AUTOSAR XML (schema 4-1-3)
standard types defined: boolean, sint8, uint16, uint32, uint8, boolean_CompuMethod, boolean_DataConstr, sint8_DataConstr, uint16_DataConstr, uint32_DataConstr, uint8_DataConstr
package /MICROSAR/Dem_swc/DataTypes
  5 x impl type:
    Dem_DebounceResetStatusType: compu {0=DEM_DEBOUNCE_STATUS_FREEZE, 1=DEM_DEBOUNCE_STATUS_RESET}, range raw 0..255, implementation-data-type=ImplementationDataTypes/uint8
    Dem_DTCFormatType: compu {0=DEM_DTC_FORMAT_OBD, 1=DEM_DTC_FORMAT_UDS, 2=DEM_DTC_FORMAT_J1939}, range raw 0..2, implementation-data-type=ImplementationDataTypes/uint8
    Dem_EventStatusType:
      compu {0=DEM_EVENT_STATUS_PASSED, 1=DEM_EVENT_STATUS_FAILED, 2=DEM_EVENT_STATUS_PREPASSED, 3=DEM_EVENT_STATUS_PREFAILED, 4=DEM_EVENT_STATUS_FDC_THRESHOLD_REACHED, 5=DEM_EVENT_STATUS_PASSED_CONDITIONS_NOT_FULFILLED, 6=DEM_EVENT_STATUS_FAILED_CONDITIONS_NOT_FULFILLED, 7=DEM_EVENT_STATUS_PREPASSED_CONDITIONS_NOT_FULFILLED, 8=DEM_EVENT_STATUS_PREFAILED_CONDITIONS_NOT_FULFILLED}
      range raw 0..255
      implementation-data-type=ImplementationDataTypes/uint8
    Dem_MaxDataValueType: category=ARRAY, sw-calibration-access=READ-ONLY
      element Dem_MaxDataValueTypeElement: array-size=14, array-size-semantics=FIXED-SIZE, implementation-data-type=ImplementationDataTypes/uint8
    Dem_UdsStatusByteType:
      compu {mask 1: 1=DEM_UDS_STATUS_TF (bit 0: TestFailed), mask 2: 2=DEM_UDS_STATUS_TFTOC (bit 1: TestFailedThisOperationCycle), mask 4: 4=DEM_UDS_STATUS_PDTC (bit 2: PendingDTC), mask 8: 8=DEM_UDS_STATUS_CDTC (bit 3: ConfirmedDTC), mask 16: 16=DEM_UDS_STATUS_TNCSLC (bit 4: TestNotCompletedSinceLastClear), mask 32: 32=DEM_UDS_STATUS_TFSLC (bit 5: TestFailedSinceLastClear), mask 64: 64=DEM_UDS_STATUS_TNCTOC (bit 6: TestNotCompletedThisOperationCycle), mask 128: 128=DEM_UDS_STATUS_WIR (bit 7: WarningIndicatorRequested)}
      range raw 0..255
      implementation-data-type=ImplementationDataTypes/uint8
package /MICROSAR/Dem_swc/Interfaces
  client server interface DiagnosticMonitor: is-service=true, service-kind=DIAGNOSTIC-EVENT-MANAGER
    11 x operation:
      GetDTCOfEvent: possible-error=[DEM_E_NO_DTC_AVAILABLE, DiagnosticMonitor/E_NOT_OK]
        arg DTCFormat: type=Dem_DTCFormatType, direction=IN, server-argument-impl-policy=USE-ARGUMENT-TYPE
        arg DTCOfEvent: type=ImplementationDataTypes/uint32, direction=OUT, server-argument-impl-policy=USE-ARGUMENT-TYPE
      GetEventExtendedDataRecordEx: possible-error=[DEM_BUFFER_TOO_SMALL, DEM_NO_SUCH_ELEMENT, DiagnosticMonitor/E_NOT_OK]
        arg RecordNumber: type=ImplementationDataTypes/uint8, direction=IN, server-argument-impl-policy=USE-ARGUMENT-TYPE
        arg DestBuffer: type=Dem_MaxDataValueType, direction=OUT, server-argument-impl-policy=USE-ARGUMENT-TYPE
        arg BufSize: type=ImplementationDataTypes/uint16, direction=INOUT, server-argument-impl-policy=USE-ARGUMENT-TYPE
      GetEventFailed: possible-error=DiagnosticMonitor/E_NOT_OK
        arg EventFailed: type=ImplementationDataTypes/boolean, direction=OUT, server-argument-impl-policy=USE-ARGUMENT-TYPE
      GetEventFreezeFrameDataEx: possible-error=[DEM_BUFFER_TOO_SMALL, DEM_NO_SUCH_ELEMENT, DiagnosticMonitor/E_NOT_OK]
        4 x arg, all with server-argument-impl-policy=USE-ARGUMENT-TYPE:
          RecordNumber: type=ImplementationDataTypes/uint8, direction=IN
          DataId: type=ImplementationDataTypes/uint16, direction=IN
          DestBuffer: type=Dem_MaxDataValueType, direction=OUT
          BufSize: type=ImplementationDataTypes/uint16, direction=INOUT
      GetEventStatus: possible-error=DiagnosticMonitor/E_NOT_OK
        arg UDSStatusByte: type=Dem_UdsStatusByteType, direction=OUT, server-argument-impl-policy=USE-ARGUMENT-TYPE
      GetEventTested: possible-error=DiagnosticMonitor/E_NOT_OK
        arg EventTested: type=ImplementationDataTypes/boolean, direction=OUT, server-argument-impl-policy=USE-ARGUMENT-TYPE
      GetEventUdsStatus: possible-error=DiagnosticMonitor/E_NOT_OK
        arg UDSStatusByte: type=Dem_UdsStatusByteType, direction=OUT, server-argument-impl-policy=USE-ARGUMENT-TYPE
      GetFaultDetectionCounter: possible-error=[DEM_E_NO_FDC_AVAILABLE, DiagnosticMonitor/E_NOT_OK]
        arg FaultDetectionCounter: type=sint8, direction=OUT, server-argument-impl-policy=USE-ARGUMENT-TYPE
      ResetEventDebounceStatus: possible-error=DiagnosticMonitor/E_NOT_OK
        arg DebounceResetStatus: type=Dem_DebounceResetStatusType, direction=IN, server-argument-impl-policy=USE-ARGUMENT-TYPE
      ResetEventStatus: possible-error=DiagnosticMonitor/E_NOT_OK
      SetEventStatus: possible-error=DiagnosticMonitor/E_NOT_OK
        arg EventStatus: type=Dem_EventStatusType, direction=IN, server-argument-impl-policy=USE-ARGUMENT-TYPE
    5 x error:
      DEM_BUFFER_TOO_SMALL: error-code=21
      DEM_E_NO_DTC_AVAILABLE: error-code=10
      DEM_E_NO_FDC_AVAILABLE: error-code=14
      DEM_NO_SUCH_ELEMENT: error-code=48
      E_NOT_OK: error-code=1
package /UAES/ASW/CompuMethods
  compu method CM_boolean: 0=FALSE, 1=TRUE
package /UAES/ASW/DataConstrs
  range DC_boolean: raw 0..1
  range DC_uint16: raw 0..65535
  range DC_uint32: raw 0..4294967295
  range DC_uint8: raw 0..255
package /UAES/ASW/DataTypeMappingSets
  data type mapping set EFuse_Mon
package /UAES/ASW/ImplementationDataTypes
  impl type rt_Array_uint16_25: category=ARRAY, sw-calibration-access=READ-ONLY, type-emitter=RTE
    element rt_Array_uint16_25: array-size=25, array-size-semantics=FIXED-SIZE, implementation-data-type=ImplementationDataTypes/uint16
  impl type rt_Array_uint32_9: category=ARRAY, sw-calibration-access=READ-ONLY, type-emitter=RTE
    element rt_Array_uint32_9: array-size=9, array-size-semantics=FIXED-SIZE, implementation-data-type=ImplementationDataTypes/uint32
  impl type rt_Array_uint8_9: category=ARRAY, sw-calibration-access=READ-ONLY, type-emitter=RTE
    element rt_Array_uint8_9: array-size=9, array-size-semantics=FIXED-SIZE, implementation-data-type=ImplementationDataTypes/uint8
package /UAES/ASW/PortInterfaces
  client server interface EFuse_ActMode_Get
    operation EFuse_SleepState_Get: possible-error=EFuse_ActMode_Get/E_NOT_OK
      arg EFuse_ID: type=ImplementationDataTypes/uint16, direction=IN, server-argument-impl-policy=USE-ARGUMENT-TYPE
      arg SleepState: type=ImplementationDataTypes/uint8, direction=OUT, server-argument-impl-policy=USE-ARGUMENT-TYPE
    error E_NOT_OK: error-code=1
  client server interface EFuse_Current_Get
    operation EFuse_Current_Get: possible-error=EFuse_Current_Get/E_NOT_OK
      arg EFuse_ID: type=ImplementationDataTypes/uint16, direction=IN, server-argument-impl-policy=USE-ARGUMENT-TYPE
      arg CurrRaw: type=ImplementationDataTypes/uint32, direction=OUT, server-argument-impl-policy=USE-ARGUMENT-TYPE
    error E_NOT_OK: error-code=1
  client server interface EFuse_DiagInfo_Get
    operation EFuse_DiagInfo_Get: possible-error=EFuse_DiagInfo_Get/E_NOT_OK
      arg EFuse_ID: type=ImplementationDataTypes/uint16, direction=IN, server-argument-impl-policy=USE-ARGUMENT-TYPE
      arg DiagInfo: type=ImplementationDataTypes/uint32, direction=OUT, server-argument-impl-policy=USE-ARGUMENT-TYPE
    error E_NOT_OK: error-code=1
  7 x sender receiver interface:
    EFuse_au32CurrFild: invalidation-policy{data-element=EFuse_au32CurrFild/Val, handle-invalid=DONT-INVALIDATE}
      data Val: sw-calibration-access=READ-ONLY, type=rt_Array_uint32_9
    EFuse_au32ErrInfo: invalidation-policy{data-element=EFuse_au32ErrInfo/Val, handle-invalid=DONT-INVALIDATE}
      data Val: sw-calibration-access=READ-ONLY, type=rt_Array_uint32_9
    EFuse_au8stFuse: invalidation-policy{data-element=EFuse_au8stFuse/Val, handle-invalid=DONT-INVALIDATE}
      data Val: sw-calibration-access=READ-ONLY, type=rt_Array_uint8_9
    EFuse_au8stSleep: invalidation-policy{data-element=EFuse_au8stSleep/Val, handle-invalid=DONT-INVALIDATE}
      data Val: sw-calibration-access=READ-ONLY, type=rt_Array_uint8_9
    gPRM_au16OvrCurrDebTime: invalidation-policy{data-element=gPRM_au16OvrCurrDebTime/Val, handle-invalid=DONT-INVALIDATE}
      data Val: sw-calibration-access=READ-ONLY, type=rt_Array_uint16_25
    gPRM_au16OvrCurrThres: invalidation-policy{data-element=gPRM_au16OvrCurrThres/Val, handle-invalid=DONT-INVALIDATE}
      data Val: sw-calibration-access=READ-ONLY, type=rt_Array_uint16_25
    gVRM_u16BatteryVolt_mv: invalidation-policy{data-element=gVRM_u16BatteryVolt_mv/Val, handle-invalid=DONT-INVALIDATE}
      data Val: sw-calibration-access=READ-ONLY, type=ImplementationDataTypes/uint16
package /UAES/ASW/SwAddrMethods
  sw addr method CALDATA
package /UAES/ASW/SwComponentTypes
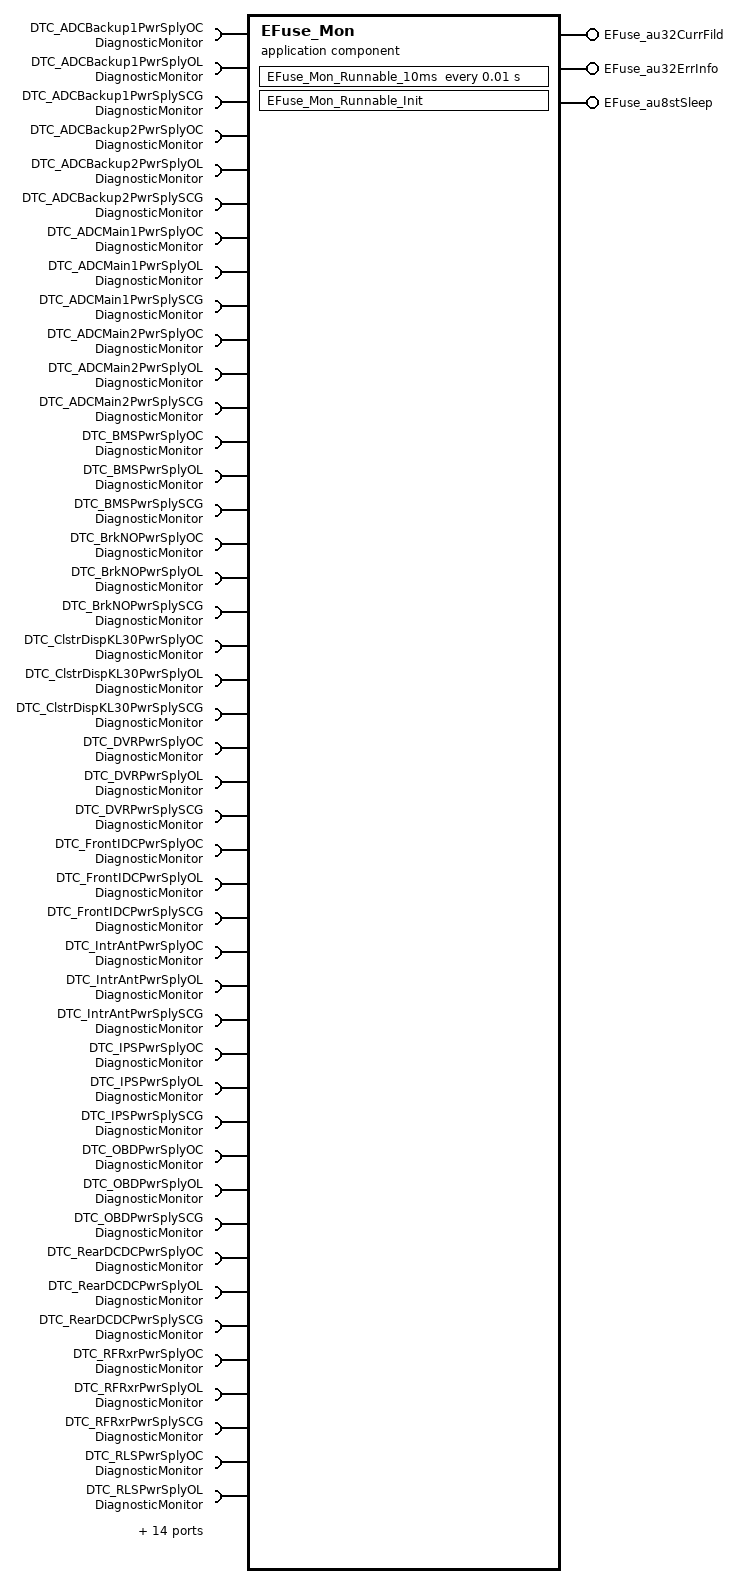
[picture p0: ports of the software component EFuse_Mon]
  application sw component type EFuse_Mon
    provide port EFuse_au32CurrFild: nonqueued-sender-com-spec{data-element=EFuse_au32CurrFild/Val, init-value=9 x 0}, provided-interface=EFuse_au32CurrFild
    provide port EFuse_au32ErrInfo: nonqueued-sender-com-spec{data-element=EFuse_au32ErrInfo/Val, init-value=9 x 0}, provided-interface=EFuse_au32ErrInfo
    provide port EFuse_au8stSleep: nonqueued-sender-com-spec{data-element=EFuse_au8stSleep/Val, init-value=9 x 0}, provided-interface=EFuse_au8stSleep
    58 x require port:
      DTC_ADCBackup1PwrSplyOC: required-interface=DiagnosticMonitor
        required-com-specs:
          GetDTCOfEvent
          GetEventExtendedDataRecordEx
          GetEventFailed
          GetEventFreezeFrameDataEx
          GetEventStatus
          GetEventTested
          GetEventUdsStatus
          GetFaultDetectionCounter
          ResetEventDebounceStatus
          ResetEventStatus
          SetEventStatus
      DTC_ADCBackup1PwrSplyOL: required-interface=DiagnosticMonitor
        required-com-specs:
          GetDTCOfEvent
          GetEventExtendedDataRecordEx
          GetEventFailed
          GetEventFreezeFrameDataEx
          GetEventStatus
          GetEventTested
          GetEventUdsStatus
          GetFaultDetectionCounter
          ResetEventDebounceStatus
          ResetEventStatus
          SetEventStatus
      DTC_ADCBackup1PwrSplySCG: required-interface=DiagnosticMonitor
        required-com-specs:
          GetDTCOfEvent
          GetEventExtendedDataRecordEx
          GetEventFailed
          GetEventFreezeFrameDataEx
          GetEventStatus
          GetEventTested
          GetEventUdsStatus
          GetFaultDetectionCounter
          ResetEventDebounceStatus
          ResetEventStatus
          SetEventStatus
      DTC_ADCBackup2PwrSplyOC: required-interface=DiagnosticMonitor
        required-com-specs:
          GetDTCOfEvent
          GetEventExtendedDataRecordEx
          GetEventFailed
          GetEventFreezeFrameDataEx
          GetEventStatus
          GetEventTested
          GetEventUdsStatus
          GetFaultDetectionCounter
          ResetEventDebounceStatus
          ResetEventStatus
          SetEventStatus
      DTC_ADCBackup2PwrSplyOL: required-interface=DiagnosticMonitor
        required-com-specs:
          GetDTCOfEvent
          GetEventExtendedDataRecordEx
          GetEventFailed
          GetEventFreezeFrameDataEx
          GetEventStatus
          GetEventTested
          GetEventUdsStatus
          GetFaultDetectionCounter
          ResetEventDebounceStatus
          ResetEventStatus
          SetEventStatus
      DTC_ADCBackup2PwrSplySCG: required-interface=DiagnosticMonitor
        required-com-specs:
          GetDTCOfEvent
          GetEventExtendedDataRecordEx
          GetEventFailed
          GetEventFreezeFrameDataEx
          GetEventStatus
          GetEventTested
          GetEventUdsStatus
          GetFaultDetectionCounter
          ResetEventDebounceStatus
          ResetEventStatus
          SetEventStatus
      DTC_ADCMain1PwrSplyOC: required-interface=DiagnosticMonitor
        required-com-specs:
          GetDTCOfEvent
          GetEventExtendedDataRecordEx
          GetEventFailed
          GetEventFreezeFrameDataEx
          GetEventStatus
          GetEventTested
          GetEventUdsStatus
          GetFaultDetectionCounter
          ResetEventDebounceStatus
          ResetEventStatus
          SetEventStatus
      DTC_ADCMain1PwrSplyOL: required-interface=DiagnosticMonitor
        required-com-specs:
          GetDTCOfEvent
          GetEventExtendedDataRecordEx
          GetEventFailed
          GetEventFreezeFrameDataEx
          GetEventStatus
          GetEventTested
          GetEventUdsStatus
          GetFaultDetectionCounter
          ResetEventDebounceStatus
          ResetEventStatus
          SetEventStatus
      DTC_ADCMain1PwrSplySCG: required-interface=DiagnosticMonitor
        required-com-specs:
          GetDTCOfEvent
          GetEventExtendedDataRecordEx
          GetEventFailed
          GetEventFreezeFrameDataEx
          GetEventStatus
          GetEventTested
          GetEventUdsStatus
          GetFaultDetectionCounter
          ResetEventDebounceStatus
          ResetEventStatus
          SetEventStatus
      DTC_ADCMain2PwrSplyOC: required-interface=DiagnosticMonitor
        required-com-specs:
          GetDTCOfEvent
          GetEventExtendedDataRecordEx
          GetEventFailed
          GetEventFreezeFrameDataEx
          GetEventStatus
          GetEventTested
          GetEventUdsStatus
          GetFaultDetectionCounter
          ResetEventDebounceStatus
          ResetEventStatus
          SetEventStatus
      DTC_ADCMain2PwrSplyOL: required-interface=DiagnosticMonitor
        required-com-specs:
          GetDTCOfEvent
          GetEventExtendedDataRecordEx
          GetEventFailed
          GetEventFreezeFrameDataEx
          GetEventStatus
          GetEventTested
          GetEventUdsStatus
          GetFaultDetectionCounter
          ResetEventDebounceStatus
          ResetEventStatus
          SetEventStatus
      DTC_ADCMain2PwrSplySCG: required-interface=DiagnosticMonitor
        required-com-specs:
          GetDTCOfEvent
          GetEventExtendedDataRecordEx
          GetEventFailed
          GetEventFreezeFrameDataEx
          GetEventStatus
          GetEventTested
          GetEventUdsStatus
          GetFaultDetectionCounter
          ResetEventDebounceStatus
          ResetEventStatus
          SetEventStatus
      DTC_BMSPwrSplyOC: required-interface=DiagnosticMonitor
        required-com-specs:
          GetDTCOfEvent
          GetEventExtendedDataRecordEx
          GetEventFailed
          GetEventFreezeFrameDataEx
          GetEventStatus
          GetEventTested
          GetEventUdsStatus
          GetFaultDetectionCounter
          ResetEventDebounceStatus
          ResetEventStatus
          SetEventStatus
      DTC_BMSPwrSplyOL: required-interface=DiagnosticMonitor
        required-com-specs:
          GetDTCOfEvent
          GetEventExtendedDataRecordEx
          GetEventFailed
          GetEventFreezeFrameDataEx
          GetEventStatus
          GetEventTested
          GetEventUdsStatus
          GetFaultDetectionCounter
          ResetEventDebounceStatus
          ResetEventStatus
          SetEventStatus
      DTC_BMSPwrSplySCG: required-interface=DiagnosticMonitor
        required-com-specs:
          GetDTCOfEvent
          GetEventExtendedDataRecordEx
          GetEventFailed
          GetEventFreezeFrameDataEx
          GetEventStatus
          GetEventTested
          GetEventUdsStatus
          GetFaultDetectionCounter
          ResetEventDebounceStatus
          ResetEventStatus
          SetEventStatus
      DTC_BrkNOPwrSplyOC: required-interface=DiagnosticMonitor
        required-com-specs:
          GetDTCOfEvent
          GetEventExtendedDataRecordEx
          GetEventFailed
          GetEventFreezeFrameDataEx
          GetEventStatus
          GetEventTested
          GetEventUdsStatus
          GetFaultDetectionCounter
          ResetEventDebounceStatus
          ResetEventStatus
          SetEventStatus
      DTC_BrkNOPwrSplyOL: required-interface=DiagnosticMonitor
        required-com-specs:
          GetDTCOfEvent
          GetEventExtendedDataRecordEx
          GetEventFailed
          GetEventFreezeFrameDataEx
          GetEventStatus
          GetEventTested
          GetEventUdsStatus
          GetFaultDetectionCounter
          ResetEventDebounceStatus
          ResetEventStatus
          SetEventStatus
      DTC_BrkNOPwrSplySCG: required-interface=DiagnosticMonitor
        required-com-specs:
          GetDTCOfEvent
          GetEventExtendedDataRecordEx
          GetEventFailed
          GetEventFreezeFrameDataEx
          GetEventStatus
          GetEventTested
          GetEventUdsStatus
          GetFaultDetectionCounter
          ResetEventDebounceStatus
          ResetEventStatus
          SetEventStatus
      DTC_ClstrDispKL30PwrSplyOC: required-interface=DiagnosticMonitor
        required-com-specs:
          GetDTCOfEvent
          GetEventExtendedDataRecordEx
          GetEventFailed
          GetEventFreezeFrameDataEx
          GetEventStatus
          GetEventTested
          GetEventUdsStatus
          GetFaultDetectionCounter
          ResetEventDebounceStatus
          ResetEventStatus
          SetEventStatus
      DTC_ClstrDispKL30PwrSplyOL: required-interface=DiagnosticMonitor
        required-com-specs:
          GetDTCOfEvent
          GetEventExtendedDataRecordEx
          GetEventFailed
          GetEventFreezeFrameDataEx
          GetEventStatus
          GetEventTested
          GetEventUdsStatus
          GetFaultDetectionCounter
          ResetEventDebounceStatus
          ResetEventStatus
          SetEventStatus
      DTC_ClstrDispKL30PwrSplySCG: required-interface=DiagnosticMonitor
        required-com-specs:
          GetDTCOfEvent
          GetEventExtendedDataRecordEx
          GetEventFailed
          GetEventFreezeFrameDataEx
          GetEventStatus
          GetEventTested
          GetEventUdsStatus
          GetFaultDetectionCounter
          ResetEventDebounceStatus
          ResetEventStatus
          SetEventStatus
      DTC_DVRPwrSplyOC: required-interface=DiagnosticMonitor
        required-com-specs:
          GetDTCOfEvent
          GetEventExtendedDataRecordEx
          GetEventFailed
          GetEventFreezeFrameDataEx
          GetEventStatus
          GetEventTested
          GetEventUdsStatus
          GetFaultDetectionCounter
          ResetEventDebounceStatus
          ResetEventStatus
          SetEventStatus
      DTC_DVRPwrSplyOL: required-interface=DiagnosticMonitor
        required-com-specs:
          GetDTCOfEvent
          GetEventExtendedDataRecordEx
          GetEventFailed
          GetEventFreezeFrameDataEx
          GetEventStatus
          GetEventTested
          GetEventUdsStatus
          GetFaultDetectionCounter
          ResetEventDebounceStatus
          ResetEventStatus
          SetEventStatus
      DTC_DVRPwrSplySCG: required-interface=DiagnosticMonitor
        required-com-specs:
          GetDTCOfEvent
          GetEventExtendedDataRecordEx
          GetEventFailed
          GetEventFreezeFrameDataEx
          GetEventStatus
          GetEventTested
          GetEventUdsStatus
          GetFaultDetectionCounter
          ResetEventDebounceStatus
          ResetEventStatus
          SetEventStatus
      DTC_FrontIDCPwrSplyOC: required-interface=DiagnosticMonitor
        required-com-specs:
          GetDTCOfEvent
          GetEventExtendedDataRecordEx
          GetEventFailed
          GetEventFreezeFrameDataEx
          GetEventStatus
          GetEventTested
          GetEventUdsStatus
          GetFaultDetectionCounter
          ResetEventDebounceStatus
          ResetEventStatus
          SetEventStatus
      DTC_FrontIDCPwrSplyOL: required-interface=DiagnosticMonitor
        required-com-specs:
          GetDTCOfEvent
          GetEventExtendedDataRecordEx
          GetEventFailed
          GetEventFreezeFrameDataEx
          GetEventStatus
          GetEventTested
          GetEventUdsStatus
          GetFaultDetectionCounter
          ResetEventDebounceStatus
          ResetEventStatus
          SetEventStatus
      DTC_FrontIDCPwrSplySCG: required-interface=DiagnosticMonitor
        required-com-specs:
          GetDTCOfEvent
          GetEventExtendedDataRecordEx
          GetEventFailed
          GetEventFreezeFrameDataEx
          GetEventStatus
          GetEventTested
          GetEventUdsStatus
          GetFaultDetectionCounter
          ResetEventDebounceStatus
          ResetEventStatus
          SetEventStatus
      DTC_IntrAntPwrSplyOC: required-interface=DiagnosticMonitor
        required-com-specs:
          GetDTCOfEvent
          GetEventExtendedDataRecordEx
          GetEventFailed
          GetEventFreezeFrameDataEx
          GetEventStatus
          GetEventTested
          GetEventUdsStatus
          GetFaultDetectionCounter
          ResetEventDebounceStatus
          ResetEventStatus
          SetEventStatus
      DTC_IntrAntPwrSplyOL: required-interface=DiagnosticMonitor
        required-com-specs:
          GetDTCOfEvent
          GetEventExtendedDataRecordEx
          GetEventFailed
          GetEventFreezeFrameDataEx
          GetEventStatus
          GetEventTested
          GetEventUdsStatus
          GetFaultDetectionCounter
          ResetEventDebounceStatus
          ResetEventStatus
          SetEventStatus
      DTC_IntrAntPwrSplySCG: required-interface=DiagnosticMonitor
        required-com-specs:
          GetDTCOfEvent
          GetEventExtendedDataRecordEx
          GetEventFailed
          GetEventFreezeFrameDataEx
          GetEventStatus
          GetEventTested
          GetEventUdsStatus
          GetFaultDetectionCounter
          ResetEventDebounceStatus
          ResetEventStatus
          SetEventStatus
      DTC_IPSPwrSplyOC: required-interface=DiagnosticMonitor
        required-com-specs:
          GetDTCOfEvent
          GetEventExtendedDataRecordEx
          GetEventFailed
          GetEventFreezeFrameDataEx
          GetEventStatus
          GetEventTested
          GetEventUdsStatus
          GetFaultDetectionCounter
          ResetEventDebounceStatus
          ResetEventStatus
          SetEventStatus
      DTC_IPSPwrSplyOL: required-interface=DiagnosticMonitor
        required-com-specs:
          GetDTCOfEvent
          GetEventExtendedDataRecordEx
          GetEventFailed
          GetEventFreezeFrameDataEx
          GetEventStatus
          GetEventTested
          GetEventUdsStatus
          GetFaultDetectionCounter
          ResetEventDebounceStatus
          ResetEventStatus
          SetEventStatus
      DTC_IPSPwrSplySCG: required-interface=DiagnosticMonitor
        required-com-specs:
          GetDTCOfEvent
          GetEventExtendedDataRecordEx
          GetEventFailed
          GetEventFreezeFrameDataEx
          GetEventStatus
          GetEventTested
          GetEventUdsStatus
          GetFaultDetectionCounter
          ResetEventDebounceStatus
          ResetEventStatus
          SetEventStatus
      DTC_OBDPwrSplyOC: required-interface=DiagnosticMonitor
        required-com-specs:
          GetDTCOfEvent
          GetEventExtendedDataRecordEx
          GetEventFailed
          GetEventFreezeFrameDataEx
          GetEventStatus
          GetEventTested
          GetEventUdsStatus
          GetFaultDetectionCounter
          ResetEventDebounceStatus
          ResetEventStatus
          SetEventStatus
      DTC_OBDPwrSplyOL: required-interface=DiagnosticMonitor
        required-com-specs:
          GetDTCOfEvent
          GetEventExtendedDataRecordEx
          GetEventFailed
          GetEventFreezeFrameDataEx
          GetEventStatus
          GetEventTested
          GetEventUdsStatus
          GetFaultDetectionCounter
          ResetEventDebounceStatus
          ResetEventStatus
          SetEventStatus
      DTC_OBDPwrSplySCG: required-interface=DiagnosticMonitor
        required-com-specs:
          GetDTCOfEvent
          GetEventExtendedDataRecordEx
          GetEventFailed
          GetEventFreezeFrameDataEx
          GetEventStatus
          GetEventTested
          GetEventUdsStatus
          GetFaultDetectionCounter
          ResetEventDebounceStatus
          ResetEventStatus
          SetEventStatus
      DTC_RearDCDCPwrSplyOC: required-interface=DiagnosticMonitor
        required-com-specs:
          GetDTCOfEvent
          GetEventExtendedDataRecordEx
          GetEventFailed
          GetEventFreezeFrameDataEx
          GetEventStatus
          GetEventTested
          GetEventUdsStatus
          GetFaultDetectionCounter
          ResetEventDebounceStatus
          ResetEventStatus
          SetEventStatus
      DTC_RearDCDCPwrSplyOL: required-interface=DiagnosticMonitor
        required-com-specs:
          GetDTCOfEvent
          GetEventExtendedDataRecordEx
          GetEventFailed
          GetEventFreezeFrameDataEx
          GetEventStatus
          GetEventTested
          GetEventUdsStatus
          GetFaultDetectionCounter
          ResetEventDebounceStatus
          ResetEventStatus
          SetEventStatus
      DTC_RearDCDCPwrSplySCG: required-interface=DiagnosticMonitor
        required-com-specs:
          GetDTCOfEvent
          GetEventExtendedDataRecordEx
          GetEventFailed
          GetEventFreezeFrameDataEx
          GetEventStatus
          GetEventTested
          GetEventUdsStatus
          GetFaultDetectionCounter
          ResetEventDebounceStatus
          ResetEventStatus
          SetEventStatus
      DTC_RFRxrPwrSplyOC: required-interface=DiagnosticMonitor
        required-com-specs:
          GetDTCOfEvent
          GetEventExtendedDataRecordEx
          GetEventFailed
          GetEventFreezeFrameDataEx
          GetEventStatus
          GetEventTested
          GetEventUdsStatus
          GetFaultDetectionCounter
          ResetEventDebounceStatus
          ResetEventStatus
          SetEventStatus
      DTC_RFRxrPwrSplyOL: required-interface=DiagnosticMonitor
        required-com-specs:
          GetDTCOfEvent
          GetEventExtendedDataRecordEx
          GetEventFailed
          GetEventFreezeFrameDataEx
          GetEventStatus
          GetEventTested
          GetEventUdsStatus
          GetFaultDetectionCounter
          ResetEventDebounceStatus
          ResetEventStatus
          SetEventStatus
      DTC_RFRxrPwrSplySCG: required-interface=DiagnosticMonitor
        required-com-specs:
          GetDTCOfEvent
          GetEventExtendedDataRecordEx
          GetEventFailed
          GetEventFreezeFrameDataEx
          GetEventStatus
          GetEventTested
          GetEventUdsStatus
          GetFaultDetectionCounter
          ResetEventDebounceStatus
          ResetEventStatus
          SetEventStatus
      DTC_RLSPwrSplyOC: required-interface=DiagnosticMonitor
        required-com-specs:
          GetDTCOfEvent
          GetEventExtendedDataRecordEx
          GetEventFailed
          GetEventFreezeFrameDataEx
          GetEventStatus
          GetEventTested
          GetEventUdsStatus
          GetFaultDetectionCounter
          ResetEventDebounceStatus
          ResetEventStatus
          SetEventStatus
      DTC_RLSPwrSplyOL: required-interface=DiagnosticMonitor
        required-com-specs:
          GetDTCOfEvent
          GetEventExtendedDataRecordEx
          GetEventFailed
          GetEventFreezeFrameDataEx
          GetEventStatus
          GetEventTested
          GetEventUdsStatus
          GetFaultDetectionCounter
          ResetEventDebounceStatus
          ResetEventStatus
          SetEventStatus
      DTC_RLSPwrSplySCG: required-interface=DiagnosticMonitor
        required-com-specs:
          GetDTCOfEvent
          GetEventExtendedDataRecordEx
          GetEventFailed
          GetEventFreezeFrameDataEx
          GetEventStatus
          GetEventTested
          GetEventUdsStatus
          GetFaultDetectionCounter
          ResetEventDebounceStatus
          ResetEventStatus
          SetEventStatus
      DTC_SAMPwrSplyOC: required-interface=DiagnosticMonitor
        required-com-specs:
          GetDTCOfEvent
          GetEventExtendedDataRecordEx
          GetEventFailed
          GetEventFreezeFrameDataEx
          GetEventStatus
          GetEventTested
          GetEventUdsStatus
          GetFaultDetectionCounter
          ResetEventDebounceStatus
          ResetEventStatus
          SetEventStatus
      DTC_SAMPwrSplyOL: required-interface=DiagnosticMonitor
        required-com-specs:
          GetDTCOfEvent
          GetEventExtendedDataRecordEx
          GetEventFailed
          GetEventFreezeFrameDataEx
          GetEventStatus
          GetEventTested
          GetEventUdsStatus
          GetFaultDetectionCounter
          ResetEventDebounceStatus
          ResetEventStatus
          SetEventStatus
      DTC_SAMPwrSplySCG: required-interface=DiagnosticMonitor
        required-com-specs:
          GetDTCOfEvent
          GetEventExtendedDataRecordEx
          GetEventFailed
          GetEventFreezeFrameDataEx
          GetEventStatus
          GetEventTested
          GetEventUdsStatus
          GetFaultDetectionCounter
          ResetEventDebounceStatus
          ResetEventStatus
          SetEventStatus
      DTC_TBoxPwrSplyOC: required-interface=DiagnosticMonitor
        required-com-specs:
          GetDTCOfEvent
          GetEventExtendedDataRecordEx
          GetEventFailed
          GetEventFreezeFrameDataEx
          GetEventStatus
          GetEventTested
          GetEventUdsStatus
          GetFaultDetectionCounter
          ResetEventDebounceStatus
          ResetEventStatus
          SetEventStatus
      DTC_TBoxPwrSplyOL: required-interface=DiagnosticMonitor
        required-com-specs:
          GetDTCOfEvent
          GetEventExtendedDataRecordEx
          GetEventFailed
          GetEventFreezeFrameDataEx
          GetEventStatus
          GetEventTested
          GetEventUdsStatus
          GetFaultDetectionCounter
          ResetEventDebounceStatus
          ResetEventStatus
          SetEventStatus
      DTC_TBoxPwrSplySCG: required-interface=DiagnosticMonitor
        required-com-specs:
          GetDTCOfEvent
          GetEventExtendedDataRecordEx
          GetEventFailed
          GetEventFreezeFrameDataEx
          GetEventStatus
          GetEventTested
          GetEventUdsStatus
          GetFaultDetectionCounter
          ResetEventDebounceStatus
          ResetEventStatus
          SetEventStatus
      EFuse_ActMode_Get: client-com-spec=EFuse_SleepState_Get, required-interface=EFuse_ActMode_Get
      EFuse_au8stFuse: nonqueued-receiver-com-spec{data-element=EFuse_au8stFuse/Val, filter=data-filter-type=ALWAYS, init-value=9 x 0}, required-interface=EFuse_au8stFuse
      EFuse_Current_Get: client-com-spec=EFuse_Current_Get, required-interface=EFuse_Current_Get
      EFuse_DiagInfo_Get: client-com-spec=EFuse_DiagInfo_Get, required-interface=EFuse_DiagInfo_Get
      gPRM_au16OvrCurrDebTime: nonqueued-receiver-com-spec{data-element=gPRM_au16OvrCurrDebTime/Val, filter=data-filter-type=ALWAYS, init-value=25 x 500}, required-interface=gPRM_au16OvrCurrDebTime
      gPRM_au16OvrCurrThres: nonqueued-receiver-com-spec{data-element=gPRM_au16OvrCurrThres/Val, filter=data-filter-type=ALWAYS, init-value=[65535, 65535, 65535, 22000, 25700, 65535, 65535, 65535, 65535, 65535, 65535, 65535, 33000, 28000, 28000, 9500, 1700, 1700, 65535, 65535, 65535, 65535, 65535, 65535, 65535]}, required-interface=gPRM_au16OvrCurrThres
      gVRM_u16BatteryVolt_mv: nonqueued-receiver-com-spec{data-element=gVRM_u16BatteryVolt_mv/Val, filter=data-filter-type=ALWAYS, init-value=0}, required-interface=gVRM_u16BatteryVolt_mv
    behavior EFuse_Mon_InternalBehavior: data-type-mapping=EFuse_Mon
      timing event TMT_EFuse_Mon_Runnable_10ms: start-on-event=EFuse_Mon_Runnable_10ms, period=0.01
      init event EFuse_Mon_Runnable_InitEvent: start-on-event=EFuse_Mon_Runnable_Init
      runnable EFuse_Mon_Runnable_10ms
        data-read-access:
          4 x access:
            READ_EFuse_au8stFuse_Val: accessed-variable=EFuse_au8stFuse.Val
            READ_gPRM_au16OvrCurrDebTime_Val: accessed-variable=gPRM_au16OvrCurrDebTime.Val
            READ_gPRM_au16OvrCurrThres_Val: accessed-variable=gPRM_au16OvrCurrThres.Val
            READ_gVRM_u16BatteryVolt_mv_Val: accessed-variable=gVRM_u16BatteryVolt_mv.Val
        data-write-access:
          access WRITE_EFuse_au32CurrRaw_Val: accessed-variable=EFuse_au32CurrFild.Val
          access WRITE_EFuse_au32ErrInfo_Val: accessed-variable=EFuse_au32ErrInfo.Val
          access WRITE_EFuse_au8stSleep_Val: accessed-variable=EFuse_au8stSleep.Val
        37 x parameter access:
          PA_EFuse_EnFuse{01..09}TestMod_C: accessed-parameter=EFuse_EnFuse{01..09}TestMod_C
          PA_EFuse_EnProtThdCal_C: accessed-parameter=EFuse_EnProtThdCal_C
          PA_EFuse_iFuse01ProtThd_C: accessed-parameter=EFuse_iFuse01ProtThd_C
          PA_EFuse_iFuse01TestMod_C: accessed-parameter=EFuse_iFuse01TestMod_C
          PA_EFuse_iFuse02ProtThd_C: accessed-parameter=EFuse_iFuse02ProtThd_C
          PA_EFuse_iFuse02TestMod_C: accessed-parameter=EFuse_iFuse02TestMod_C
          PA_EFuse_iFuse03ProtThd_C: accessed-parameter=EFuse_iFuse03ProtThd_C
          PA_EFuse_iFuse03TestMod_C: accessed-parameter=EFuse_iFuse03TestMod_C
          PA_EFuse_iFuse04ProtThd_C: accessed-parameter=EFuse_iFuse04ProtThd_C
          PA_EFuse_iFuse04TestMod_C: accessed-parameter=EFuse_iFuse04TestMod_C
          PA_EFuse_iFuse05ProtThd_C: accessed-parameter=EFuse_iFuse05ProtThd_C
          PA_EFuse_iFuse05TestMod_C: accessed-parameter=EFuse_iFuse05TestMod_C
          PA_EFuse_iFuse06ProtThd_C: accessed-parameter=EFuse_iFuse06ProtThd_C
          PA_EFuse_iFuse06TestMod_C: accessed-parameter=EFuse_iFuse06TestMod_C
          PA_EFuse_iFuse07ProtThd_C: accessed-parameter=EFuse_iFuse07ProtThd_C
          PA_EFuse_iFuse07TestMod_C: accessed-parameter=EFuse_iFuse07TestMod_C
          PA_EFuse_iFuse08ProtThd_C: accessed-parameter=EFuse_iFuse08ProtThd_C
          PA_EFuse_iFuse08TestMod_C: accessed-parameter=EFuse_iFuse08TestMod_C
          PA_EFuse_iFuse09ProtThd_C: accessed-parameter=EFuse_iFuse09ProtThd_C
          PA_EFuse_iFuse09TestMod_C: accessed-parameter=EFuse_iFuse09TestMod_C
          PA_EFuse_tiFuse{01..09}ProtEquivThd_C: accessed-parameter=EFuse_tiFuse{01..09}ProtEquivThd_C
        39 x sync call:
          SC_DTC_ADCBackup1PwrSplyOC_GetEventFailed: operation=DTC_ADCBackup1PwrSplyOC.GetEventFailed, timeout=1E-06
          SC_DTC_ADCBackup1PwrSplyOC_GetEventTested: operation=DTC_ADCBackup1PwrSplyOC.GetEventTested, timeout=1E-06
          SC_DTC_ADCBackup1PwrSplyOC_ResetEventDebounceStatus: operation=DTC_ADCBackup1PwrSplyOC.ResetEventDebounceStatus, timeout=1E-06
          SC_DTC_ADCBackup1PwrSplyOC_SetEventStatus: operation=DTC_ADCBackup1PwrSplyOC.SetEventStatus, timeout=1E-06
          SC_DTC_ADCBackup1PwrSplyOL_GetEventFailed: operation=DTC_ADCBackup1PwrSplyOL.GetEventFailed, timeout=1E-06
          SC_DTC_ADCBackup1PwrSplyOL_GetEventTested: operation=DTC_ADCBackup1PwrSplyOL.GetEventTested, timeout=1E-06
          SC_DTC_ADCBackup1PwrSplyOL_ResetEventDebounceStatus: operation=DTC_ADCBackup1PwrSplyOL.ResetEventDebounceStatus, timeout=1E-06
          SC_DTC_ADCBackup1PwrSplyOL_SetEventStatus: operation=DTC_ADCBackup1PwrSplyOL.SetEventStatus, timeout=1E-06
          SC_DTC_ADCBackup1PwrSplySCG_GetEventFailed: operation=DTC_ADCBackup1PwrSplySCG.GetEventFailed, timeout=1E-06
          SC_DTC_ADCBackup1PwrSplySCG_GetEventTested: operation=DTC_ADCBackup1PwrSplySCG.GetEventTested, timeout=1E-06
          SC_DTC_ADCBackup1PwrSplySCG_ResetEventDebounceStatus: operation=DTC_ADCBackup1PwrSplySCG.ResetEventDebounceStatus, timeout=1E-06
          SC_DTC_ADCBackup1PwrSplySCG_SetEventStatus: operation=DTC_ADCBackup1PwrSplySCG.SetEventStatus, timeout=1E-06
          SC_DTC_ADCBackup2PwrSplyOC_GetEventFailed: operation=DTC_ADCBackup2PwrSplyOC.GetEventFailed, timeout=1E-06
          SC_DTC_ADCBackup2PwrSplyOC_GetEventTested: operation=DTC_ADCBackup2PwrSplyOC.GetEventTested, timeout=1E-06
          SC_DTC_ADCBackup2PwrSplyOC_ResetEventDebounceStatus: operation=DTC_ADCBackup2PwrSplyOC.ResetEventDebounceStatus, timeout=1E-06
          SC_DTC_ADCBackup2PwrSplyOC_SetEventStatus: operation=DTC_ADCBackup2PwrSplyOC.SetEventStatus, timeout=1E-06
          SC_DTC_ADCBackup2PwrSplyOL_GetEventFailed: operation=DTC_ADCBackup2PwrSplyOL.GetEventFailed, timeout=1E-06
          SC_DTC_ADCBackup2PwrSplyOL_GetEventTested: operation=DTC_ADCBackup2PwrSplyOL.GetEventTested, timeout=1E-06
          SC_DTC_ADCBackup2PwrSplyOL_ResetEventDebounceStatus: operation=DTC_ADCBackup2PwrSplyOL.ResetEventDebounceStatus, timeout=1E-06
          SC_DTC_ADCBackup2PwrSplyOL_SetEventStatus: operation=DTC_ADCBackup2PwrSplyOL.SetEventStatus, timeout=1E-06
          SC_DTC_ADCBackup2PwrSplySCG_GetEventFailed: operation=DTC_ADCBackup2PwrSplySCG.GetEventFailed, timeout=1E-06
          SC_DTC_ADCBackup2PwrSplySCG_GetEventTested: operation=DTC_ADCBackup2PwrSplySCG.GetEventTested, timeout=1E-06
          SC_DTC_ADCBackup2PwrSplySCG_ResetEventDebounceStatus: operation=DTC_ADCBackup2PwrSplySCG.ResetEventDebounceStatus, timeout=1E-06
          SC_DTC_ADCBackup2PwrSplySCG_SetEventStatus: operation=DTC_ADCBackup2PwrSplySCG.SetEventStatus, timeout=1E-06
          SC_DTC_RearDCDCPwrSplyOC_GetEventFailed: operation=DTC_RearDCDCPwrSplyOC.GetEventFailed, timeout=1E-06
          SC_DTC_RearDCDCPwrSplyOC_GetEventTested: operation=DTC_RearDCDCPwrSplyOC.GetEventTested, timeout=1E-06
          SC_DTC_RearDCDCPwrSplyOC_ResetEventDebounceStatus: operation=DTC_RearDCDCPwrSplyOC.ResetEventDebounceStatus, timeout=1E-06
          SC_DTC_RearDCDCPwrSplyOC_SetEventStatus: operation=DTC_RearDCDCPwrSplyOC.SetEventStatus, timeout=1E-06
          SC_DTC_RearDCDCPwrSplyOL_GetEventFailed: operation=DTC_RearDCDCPwrSplyOL.GetEventFailed, timeout=1E-06
          SC_DTC_RearDCDCPwrSplyOL_GetEventTested: operation=DTC_RearDCDCPwrSplyOL.GetEventTested, timeout=1E-06
          SC_DTC_RearDCDCPwrSplyOL_ResetEventDebounceStatus: operation=DTC_RearDCDCPwrSplyOL.ResetEventDebounceStatus, timeout=1E-06
          SC_DTC_RearDCDCPwrSplyOL_SetEventStatus: operation=DTC_RearDCDCPwrSplyOL.SetEventStatus, timeout=1E-06
          SC_DTC_RearDCDCPwrSplySCG_GetEventFailed: operation=DTC_RearDCDCPwrSplySCG.GetEventFailed, timeout=1E-06
          SC_DTC_RearDCDCPwrSplySCG_GetEventTested: operation=DTC_RearDCDCPwrSplySCG.GetEventTested, timeout=1E-06
          SC_DTC_RearDCDCPwrSplySCG_ResetEventDebounceStatus: operation=DTC_RearDCDCPwrSplySCG.ResetEventDebounceStatus, timeout=1E-06
          SC_DTC_RearDCDCPwrSplySCG_SetEventStatus: operation=DTC_RearDCDCPwrSplySCG.SetEventStatus, timeout=1E-06
          SC_EFuse_ActMode_Get_EFuse_SleepState_Get: operation=EFuse_ActMode_Get.EFuse_SleepState_Get, timeout=0
          SC_EFuse_Current_Get_EFuse_Current_Get: operation=EFuse_Current_Get.EFuse_Current_Get, timeout=0
          SC_EFuse_DiagInfo_Get_EFuse_DiagInfo_Get: operation=EFuse_DiagInfo_Get.EFuse_DiagInfo_Get, timeout=0
      runnable EFuse_Mon_Runnable_Init
        37 x parameter access:
          PA_EFuse_EnFuse{01..09}TestMod_C: accessed-parameter=EFuse_EnFuse{01..09}TestMod_C
          PA_EFuse_EnProtThdCal_C: accessed-parameter=EFuse_EnProtThdCal_C
          PA_EFuse_iFuse01ProtThd_C: accessed-parameter=EFuse_iFuse01ProtThd_C
          PA_EFuse_iFuse01TestMod_C: accessed-parameter=EFuse_iFuse01TestMod_C
          PA_EFuse_iFuse02ProtThd_C: accessed-parameter=EFuse_iFuse02ProtThd_C
          PA_EFuse_iFuse02TestMod_C: accessed-parameter=EFuse_iFuse02TestMod_C
          PA_EFuse_iFuse03ProtThd_C: accessed-parameter=EFuse_iFuse03ProtThd_C
          PA_EFuse_iFuse03TestMod_C: accessed-parameter=EFuse_iFuse03TestMod_C
          PA_EFuse_iFuse04ProtThd_C: accessed-parameter=EFuse_iFuse04ProtThd_C
          PA_EFuse_iFuse04TestMod_C: accessed-parameter=EFuse_iFuse04TestMod_C
          PA_EFuse_iFuse05ProtThd_C: accessed-parameter=EFuse_iFuse05ProtThd_C
          PA_EFuse_iFuse05TestMod_C: accessed-parameter=EFuse_iFuse05TestMod_C
          PA_EFuse_iFuse06ProtThd_C: accessed-parameter=EFuse_iFuse06ProtThd_C
          PA_EFuse_iFuse06TestMod_C: accessed-parameter=EFuse_iFuse06TestMod_C
          PA_EFuse_iFuse07ProtThd_C: accessed-parameter=EFuse_iFuse07ProtThd_C
          PA_EFuse_iFuse07TestMod_C: accessed-parameter=EFuse_iFuse07TestMod_C
          PA_EFuse_iFuse08ProtThd_C: accessed-parameter=EFuse_iFuse08ProtThd_C
          PA_EFuse_iFuse08TestMod_C: accessed-parameter=EFuse_iFuse08TestMod_C
          PA_EFuse_iFuse09ProtThd_C: accessed-parameter=EFuse_iFuse09ProtThd_C
          PA_EFuse_iFuse09TestMod_C: accessed-parameter=EFuse_iFuse09TestMod_C
          PA_EFuse_tiFuse{01..09}ProtEquivThd_C: accessed-parameter=EFuse_tiFuse{01..09}ProtEquivThd_C
      shared-parameters:
        37 x parameter data prototype, all with sw-addr-method=CALDATA, sw-calibration-access=READ-WRITE, init-value=0:
          EFuse_EnFuse{01..09}TestMod_C: type=ImplementationDataTypes/boolean
          EFuse_EnProtThdCal_C: type=ImplementationDataTypes/boolean
          EFuse_iFuse01ProtThd_C: type=ImplementationDataTypes/uint32
          EFuse_iFuse01TestMod_C: type=ImplementationDataTypes/uint32
          EFuse_iFuse02ProtThd_C: type=ImplementationDataTypes/uint32
          EFuse_iFuse02TestMod_C: type=ImplementationDataTypes/uint32
          EFuse_iFuse03ProtThd_C: type=ImplementationDataTypes/uint32
          EFuse_iFuse03TestMod_C: type=ImplementationDataTypes/uint32
          EFuse_iFuse04ProtThd_C: type=ImplementationDataTypes/uint32
          EFuse_iFuse04TestMod_C: type=ImplementationDataTypes/uint32
          EFuse_iFuse05ProtThd_C: type=ImplementationDataTypes/uint32
          EFuse_iFuse05TestMod_C: type=ImplementationDataTypes/uint32
          EFuse_iFuse06ProtThd_C: type=ImplementationDataTypes/uint32
          EFuse_iFuse06TestMod_C: type=ImplementationDataTypes/uint32
          EFuse_iFuse07ProtThd_C: type=ImplementationDataTypes/uint32
          EFuse_iFuse07TestMod_C: type=ImplementationDataTypes/uint32
          EFuse_iFuse08ProtThd_C: type=ImplementationDataTypes/uint32
          EFuse_iFuse08TestMod_C: type=ImplementationDataTypes/uint32
          EFuse_iFuse09ProtThd_C: type=ImplementationDataTypes/uint32
          EFuse_iFuse09TestMod_C: type=ImplementationDataTypes/uint32
          EFuse_tiFuse{01..09}ProtEquivThd_C: type=ImplementationDataTypes/uint16
  swc implementation EFuse_Mon_Implementation: behavior=EFuse_Mon_InternalBehavior
    code-descriptors:
      code Default: artifact-descriptors=autosar-engineering-object={short-label=Default, category=SWSRC}
package /UAES/ASW/Units
  unit NoUnit: factor-si-to-unit=1, offset-si-to-unit=0
